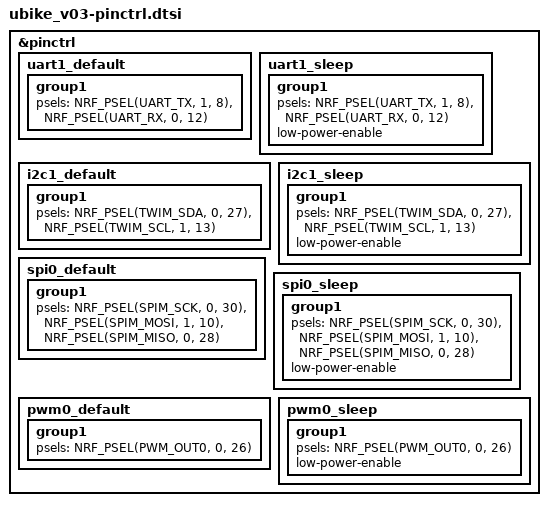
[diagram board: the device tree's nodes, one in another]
/*
 * Universal Bike Controller
 * Copyright (C) 2022-2023, Greco Engineering Solutions LLC
 *
 * This program is free software: you can redistribute it and/or modify
 * it under the terms of the GNU General Public License as published by
 * the Free Software Foundation, either version 3 of the License, or
 * (at your option) any later version.
 *
 * This program is distributed in the hope that it will be useful,
 * but WITHOUT ANY WARRANTY; without even the implied warranty of
 * MERCHANTABILITY or FITNESS FOR A PARTICULAR PURPOSE.  See the
 * GNU General Public License for more details.
 *
 * You should have received a copy of the GNU General Public License
 * along with this program.  If not, see <http://www.gnu.org/licenses/>.
 */

 &pinctrl {
	uart1_default: uart1_default {
		group1 {
			psels = <NRF_PSEL(UART_TX, 1, 8)>,
					<NRF_PSEL(UART_RX, 0, 12)>;
			//bias-pull-up;
		};
	};

	uart1_sleep: uart1_sleep {
		group1 {
			psels = <NRF_PSEL(UART_TX, 1, 8)>,
					<NRF_PSEL(UART_RX, 0, 12)>;
			low-power-enable;
		};
	};

	i2c1_default: i2c1_default {
		group1 {
			psels = <NRF_PSEL(TWIM_SDA, 0, 27)>, // XR
					<NRF_PSEL(TWIM_SCL, 1, 13)>; // XL
		};
	};

	i2c1_sleep: i2c1_sleep {
		group1 {
			psels = <NRF_PSEL(TWIM_SDA, 0, 27)>, // XR
					<NRF_PSEL(TWIM_SCL, 1, 13)>; // XL
			low-power-enable;
		};
	};

	spi0_default: spi0_default {
		group1 {
			psels = <NRF_PSEL(SPIM_SCK, 0, 30)>,  // SCL
					<NRF_PSEL(SPIM_MOSI, 1, 10)>, // SDI
					<NRF_PSEL(SPIM_MISO, 0, 28)>; // SDO
		};
	};

	spi0_sleep: spi0_sleep {
		group1 {
			psels = <NRF_PSEL(SPIM_SCK, 0, 30)>,  // SCL
					<NRF_PSEL(SPIM_MOSI, 1, 10)>, // SDI
					<NRF_PSEL(SPIM_MISO, 0, 28)>; // SDO
			low-power-enable;
		};
	};

	pwm0_default: pwm0_default {
		group1 {
			psels = <NRF_PSEL(PWM_OUT0, 0, 26)>;
		};
	};

	pwm0_sleep: pwm0_sleep {
		group1 {
			psels = <NRF_PSEL(PWM_OUT0, 0, 26)>;
			low-power-enable;
		};
	};
};
